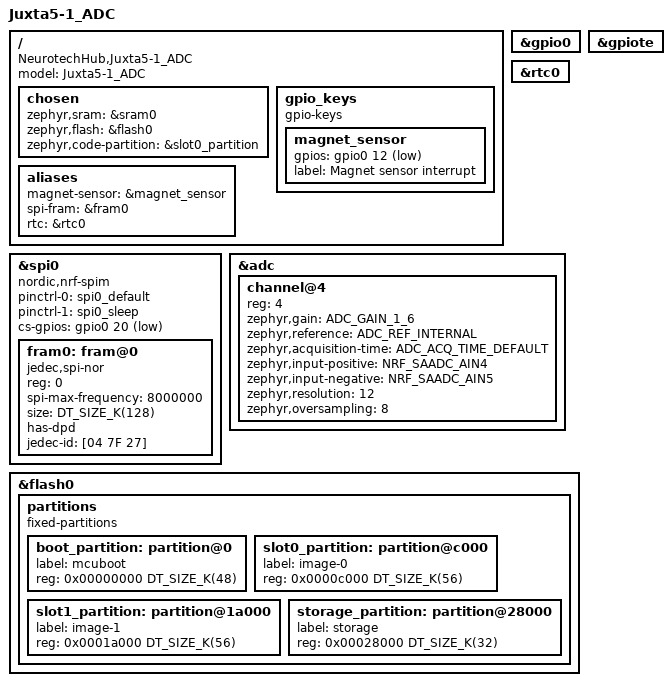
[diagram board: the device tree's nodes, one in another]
/dts-v1/;
#include <nordic/nrf52805_caaa.dtsi>
#include "Juxta5-1_ADC-pinctrl.dtsi"

/ {
	model = "Juxta5-1_ADC";
	compatible = "NeurotechHub,Juxta5-1_ADC";

	chosen {
		zephyr,sram = &sram0;
		zephyr,flash = &flash0;
		zephyr,code-partition = &slot0_partition;
	};

	gpio_keys {
		compatible = "gpio-keys";
		magnet_sensor: magnet_sensor {
			gpios = <&gpio0 12 GPIO_ACTIVE_LOW>;
			label = "Magnet sensor interrupt";
		};
	};

	aliases {
		magnet-sensor = &magnet_sensor;
		spi-fram = &fram0;
		rtc = &rtc0;
	};
};

&gpio0 {
	status = "okay";
};

&gpiote {
	status = "okay";
};

&rtc0 {
	status = "okay";
};

&spi0 {
	compatible = "nordic,nrf-spim";
	status = "okay";
	
	pinctrl-0 = <&spi0_default>;
	pinctrl-1 = <&spi0_sleep>;
	pinctrl-names = "default", "sleep";
	
	/* CS line for FRAM - active LOW as confirmed */
	cs-gpios = <&gpio0 20 GPIO_ACTIVE_LOW>;
	
	fram0: fram@0 {
		compatible = "jedec,spi-nor";
		reg = <0>;
		spi-max-frequency = <8000000>; /* 8MHz - standard SPI clock */
		size = <DT_SIZE_K(128)>; /* MB85RS1MTPW-G-APEWE1 is 1Mbit = 128KB */
		has-dpd;
		jedec-id = [04 7F 27];
	};
};

&adc {
	status = "okay";
	
	#address-cells = <1>;
	#size-cells = <0>;
	
	channel@4 {
		reg = <4>;
		zephyr,gain = "ADC_GAIN_1_6";
		zephyr,reference = "ADC_REF_INTERNAL";
		zephyr,acquisition-time = <ADC_ACQ_TIME_DEFAULT>;
		zephyr,input-positive = <NRF_SAADC_AIN4>; /* P0.04 */
		zephyr,input-negative = <NRF_SAADC_AIN5>; /* P0.05 */
		zephyr,resolution = <12>;
		zephyr,oversampling = <8>;
	};
};

&flash0 {
	partitions {
		compatible = "fixed-partitions";
		#address-cells = <1>;
		#size-cells = <1>;

		boot_partition: partition@0 {
			label = "mcuboot";
			reg = <0x00000000 DT_SIZE_K(48)>;
		};

		slot0_partition: partition@c000 {
			label = "image-0";
			reg = <0x0000c000 DT_SIZE_K(56)>;
		};

		slot1_partition: partition@1a000 {
			label = "image-1";
			reg = <0x0001a000 DT_SIZE_K(56)>;
		};

		storage_partition: partition@28000 {
			label = "storage";
			reg = <0x00028000 DT_SIZE_K(32)>;
		};
	};
};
